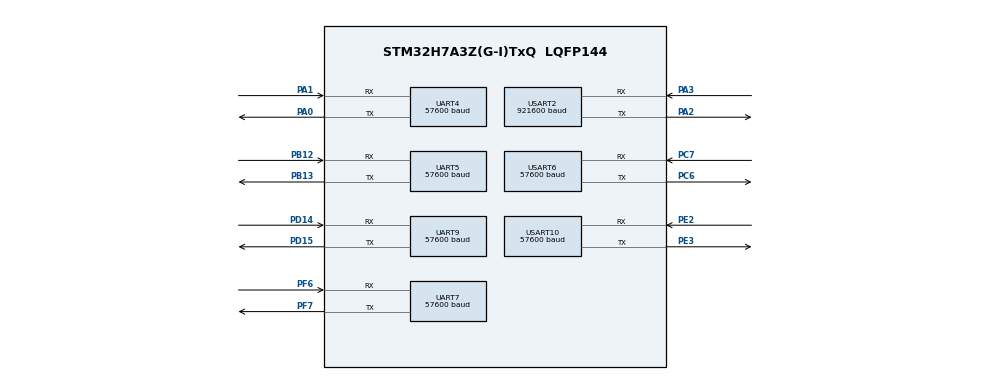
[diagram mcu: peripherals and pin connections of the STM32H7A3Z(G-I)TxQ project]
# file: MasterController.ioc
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CORTEX_M7.CPU_ICache=Enabled
CORTEX_M7.DisableExec_Spec=MPU_INSTRUCTION_ACCESS_DISABLE
CORTEX_M7.default_mode_Activation=1
Dma.Request0=UART4_RX
Dma.Request1=UART5_RX
Dma.Request2=UART7_RX
Dma.Request3=UART9_RX
Dma.Request4=USART2_RX
Dma.Request5=USART6_RX
Dma.Request6=USART10_RX
Dma.UART4_RX.0.Direction=DMA_PERIPH_TO_MEMORY
Dma.UART4_RX.0.EventEnable=DISABLE
Dma.UART4_RX.0.FIFOMode=DMA_FIFOMODE_DISABLE
Dma.UART4_RX.0.Instance=DMA1_Stream0
Dma.UART4_RX.0.MemDataAlignment=DMA_MDATAALIGN_BYTE
Dma.UART4_RX.0.MemInc=DMA_MINC_ENABLE
Dma.UART4_RX.0.Mode=DMA_CIRCULAR
Dma.UART4_RX.0.PeriphDataAlignment=DMA_PDATAALIGN_BYTE
Dma.UART4_RX.0.PeriphInc=DMA_PINC_DISABLE
Dma.UART4_RX.0.Polarity=HAL_DMAMUX_REQ_GEN_RISING
Dma.UART4_RX.0.Priority=DMA_PRIORITY_HIGH
Dma.UART4_RX.0.RequestNumber=1
Dma.UART4_RX.0.SignalID=NONE
Dma.UART4_RX.0.SyncEnable=DISABLE
Dma.UART4_RX.0.SyncPolarity=HAL_DMAMUX_SYNC_NO_EVENT
Dma.UART4_RX.0.SyncRequestNumber=1
Dma.UART4_RX.0.SyncSignalID=NONE
Dma.UART5_RX.1.Direction=DMA_PERIPH_TO_MEMORY
Dma.UART5_RX.1.EventEnable=DISABLE
Dma.UART5_RX.1.FIFOMode=DMA_FIFOMODE_DISABLE
Dma.UART5_RX.1.Instance=DMA1_Stream1
Dma.UART5_RX.1.MemDataAlignment=DMA_MDATAALIGN_BYTE
Dma.UART5_RX.1.MemInc=DMA_MINC_ENABLE
Dma.UART5_RX.1.Mode=DMA_CIRCULAR
Dma.UART5_RX.1.PeriphDataAlignment=DMA_PDATAALIGN_BYTE
Dma.UART5_RX.1.PeriphInc=DMA_PINC_DISABLE
Dma.UART5_RX.1.Polarity=HAL_DMAMUX_REQ_GEN_RISING
Dma.UART5_RX.1.Priority=DMA_PRIORITY_HIGH
Dma.UART5_RX.1.RequestNumber=1
Dma.UART5_RX.1.SignalID=NONE
Dma.UART5_RX.1.SyncEnable=DISABLE
Dma.UART5_RX.1.SyncPolarity=HAL_DMAMUX_SYNC_NO_EVENT
Dma.UART5_RX.1.SyncRequestNumber=1
Dma.UART5_RX.1.SyncSignalID=NONE
Dma.UART7_RX.2.Direction=DMA_PERIPH_TO_MEMORY
Dma.UART7_RX.2.EventEnable=DISABLE
Dma.UART7_RX.2.FIFOMode=DMA_FIFOMODE_DISABLE
Dma.UART7_RX.2.Instance=DMA1_Stream2
Dma.UART7_RX.2.MemDataAlignment=DMA_MDATAALIGN_BYTE
Dma.UART7_RX.2.MemInc=DMA_MINC_ENABLE
Dma.UART7_RX.2.Mode=DMA_CIRCULAR
Dma.UART7_RX.2.PeriphDataAlignment=DMA_PDATAALIGN_BYTE
Dma.UART7_RX.2.PeriphInc=DMA_PINC_DISABLE
Dma.UART7_RX.2.Polarity=HAL_DMAMUX_REQ_GEN_RISING
Dma.UART7_RX.2.Priority=DMA_PRIORITY_HIGH
Dma.UART7_RX.2.RequestNumber=1
Dma.UART7_RX.2.SignalID=NONE
Dma.UART7_RX.2.SyncEnable=DISABLE
Dma.UART7_RX.2.SyncPolarity=HAL_DMAMUX_SYNC_NO_EVENT
Dma.UART7_RX.2.SyncRequestNumber=1
Dma.UART7_RX.2.SyncSignalID=NONE
Dma.UART9_RX.3.Direction=DMA_PERIPH_TO_MEMORY
Dma.UART9_RX.3.EventEnable=DISABLE
Dma.UART9_RX.3.FIFOMode=DMA_FIFOMODE_DISABLE
Dma.UART9_RX.3.Instance=DMA1_Stream3
Dma.UART9_RX.3.MemDataAlignment=DMA_MDATAALIGN_BYTE
Dma.UART9_RX.3.MemInc=DMA_MINC_ENABLE
Dma.UART9_RX.3.Mode=DMA_CIRCULAR
Dma.UART9_RX.3.PeriphDataAlignment=DMA_PDATAALIGN_BYTE
Dma.UART9_RX.3.PeriphInc=DMA_PINC_DISABLE
Dma.UART9_RX.3.Polarity=HAL_DMAMUX_REQ_GEN_RISING
Dma.UART9_RX.3.Priority=DMA_PRIORITY_HIGH
Dma.UART9_RX.3.RequestNumber=1
Dma.UART9_RX.3.SignalID=NONE
Dma.UART9_RX.3.SyncEnable=DISABLE
Dma.UART9_RX.3.SyncPolarity=HAL_DMAMUX_SYNC_NO_EVENT
Dma.UART9_RX.3.SyncRequestNumber=1
Dma.UART9_RX.3.SyncSignalID=NONE
Dma.USART10_RX.6.Direction=DMA_PERIPH_TO_MEMORY
Dma.USART10_RX.6.EventEnable=DISABLE
Dma.USART10_RX.6.FIFOMode=DMA_FIFOMODE_DISABLE
Dma.USART10_RX.6.Instance=DMA1_Stream6
Dma.USART10_RX.6.MemDataAlignment=DMA_MDATAALIGN_BYTE
Dma.USART10_RX.6.MemInc=DMA_MINC_ENABLE
Dma.USART10_RX.6.Mode=DMA_CIRCULAR
Dma.USART10_RX.6.PeriphDataAlignment=DMA_PDATAALIGN_BYTE
Dma.USART10_RX.6.PeriphInc=DMA_PINC_DISABLE
Dma.USART10_RX.6.Polarity=HAL_DMAMUX_REQ_GEN_RISING
Dma.USART10_RX.6.Priority=DMA_PRIORITY_HIGH
Dma.USART10_RX.6.RequestNumber=1
Dma.USART10_RX.6.SignalID=NONE
Dma.USART10_RX.6.SyncEnable=DISABLE
Dma.USART10_RX.6.SyncPolarity=HAL_DMAMUX_SYNC_NO_EVENT
Dma.USART10_RX.6.SyncRequestNumber=1
Dma.USART10_RX.6.SyncSignalID=NONE
Dma.USART2_RX.4.Direction=DMA_PERIPH_TO_MEMORY
Dma.USART2_RX.4.EventEnable=DISABLE
Dma.USART2_RX.4.FIFOMode=DMA_FIFOMODE_DISABLE
Dma.USART2_RX.4.Instance=DMA1_Stream4
Dma.USART2_RX.4.MemDataAlignment=DMA_MDATAALIGN_BYTE
Dma.USART2_RX.4.MemInc=DMA_MINC_ENABLE
Dma.USART2_RX.4.Mode=DMA_CIRCULAR
Dma.USART2_RX.4.PeriphDataAlignment=DMA_PDATAALIGN_BYTE
Dma.USART2_RX.4.PeriphInc=DMA_PINC_DISABLE
Dma.USART2_RX.4.Polarity=HAL_DMAMUX_REQ_GEN_RISING
Dma.USART2_RX.4.Priority=DMA_PRIORITY_HIGH
Dma.USART2_RX.4.RequestNumber=1
Dma.USART2_RX.4.SignalID=NONE
Dma.USART2_RX.4.SyncEnable=DISABLE
Dma.USART2_RX.4.SyncPolarity=HAL_DMAMUX_SYNC_NO_EVENT
Dma.USART2_RX.4.SyncRequestNumber=1
Dma.USART2_RX.4.SyncSignalID=NONE
Dma.USART6_RX.5.Direction=DMA_PERIPH_TO_MEMORY
Dma.USART6_RX.5.EventEnable=DISABLE
Dma.USART6_RX.5.FIFOMode=DMA_FIFOMODE_DISABLE
Dma.USART6_RX.5.Instance=DMA1_Stream5
Dma.USART6_RX.5.MemDataAlignment=DMA_MDATAALIGN_BYTE
Dma.USART6_RX.5.MemInc=DMA_MINC_ENABLE
Dma.USART6_RX.5.Mode=DMA_CIRCULAR
Dma.USART6_RX.5.PeriphDataAlignment=DMA_PDATAALIGN_BYTE
Dma.USART6_RX.5.PeriphInc=DMA_PINC_DISABLE
Dma.USART6_RX.5.Polarity=HAL_DMAMUX_REQ_GEN_RISING
Dma.USART6_RX.5.Priority=DMA_PRIORITY_HIGH
Dma.USART6_RX.5.RequestNumber=1
Dma.USART6_RX.5.SignalID=NONE
Dma.USART6_RX.5.SyncEnable=DISABLE
Dma.USART6_RX.5.SyncPolarity=HAL_DMAMUX_SYNC_NO_EVENT
Dma.USART6_RX.5.SyncRequestNumber=1
Dma.USART6_RX.5.SyncSignalID=NONE
IWDG1.Prescaler=IWDG_PRESCALER_32
IWDG1.Reload=1000
Mcu.Family=STM32H7
Mcu.Name=STM32H7A3Z(G-I)TxQ
Mcu.Package=LQFP144
NUCLEO-H7A3ZI-Q.BUTTON=1
NUCLEO-H7A3ZI-Q.LD1=true
NUCLEO-H7A3ZI-Q.LD2=true
NUCLEO-H7A3ZI-Q.LD3=true
NUCLEO-H7A3ZI-Q.VCP=true
NVIC.DMA1_Stream0_IRQn=true\:0\:0\:false\:false\:true\:false\:true\:true
NVIC.DMA1_Stream1_IRQn=true\:0\:0\:false\:false\:true\:false\:true\:true
NVIC.DMA1_Stream2_IRQn=true\:0\:0\:false\:false\:true\:false\:true\:true
NVIC.DMA1_Stream3_IRQn=true\:0\:0\:false\:false\:true\:false\:true\:true
NVIC.DMA1_Stream4_IRQn=true\:0\:0\:false\:false\:true\:false\:true\:true
NVIC.DMA1_Stream5_IRQn=true\:0\:0\:false\:false\:true\:false\:true\:true
NVIC.DMA1_Stream6_IRQn=true\:0\:0\:false\:false\:true\:false\:true\:true
NVIC.EXTI15_10_IRQn=true\:0\:0\:false\:false\:true\:false\:true\:true
NVIC.PriorityGroup=NVIC_PRIORITYGROUP_4
NVIC.UART4_IRQn=true\:0\:0\:false\:false\:true\:true\:true\:true
NVIC.UART5_IRQn=true\:0\:0\:false\:false\:true\:true\:true\:true
NVIC.UART7_IRQn=true\:0\:0\:false\:false\:true\:true\:true\:true
NVIC.UART9_IRQn=true\:0\:0\:false\:false\:true\:true\:true\:true
NVIC.USART10_IRQn=true\:0\:0\:false\:false\:true\:true\:true\:true
NVIC.USART2_IRQn=true\:0\:0\:false\:false\:true\:true\:true\:true
NVIC.USART6_IRQn=true\:0\:0\:false\:false\:true\:true\:true\:true
PA0.Mode=Asynchronous
PA0.Signal=UART4_TX
PA1.GPIO_PuPd=GPIO_PULLUP
PA1.Mode=Asynchronous
PA1.Signal=UART4_RX
PA13.Mode=Serial_Wire
PA13.Signal=DEBUG_JTMS-SWDIO
PA14.Mode=Serial_Wire
PA14.Signal=DEBUG_JTCK-SWCLK
PA2.Mode=Asynchronous
PA2.Signal=USART2_TX
PA3.GPIO_PuPd=GPIO_PULLUP
PA3.Mode=Asynchronous
PA3.Signal=USART2_RX
PB12.GPIO_PuPd=GPIO_PULLUP
PB12.Mode=Asynchronous
PB12.Signal=UART5_RX
PB13.Mode=Asynchronous
PB13.Signal=UART5_TX
PC14-OSC32_IN.GPIO_Label=OSC32_IN
PC14-OSC32_IN.Signal=RCC_OSC32_IN
PC15-OSC32_OUT.GPIO_Label=OSC32_OUT
PC15-OSC32_OUT.Signal=RCC_OSC32_OUT
PC6.Mode=Asynchronous
PC6.Signal=USART6_TX
PC7.GPIO_PuPd=GPIO_PULLUP
PC7.Mode=Asynchronous
PC7.Signal=USART6_RX
PD14.GPIO_PuPd=GPIO_PULLUP
PD14.Mode=Asynchronous
PD14.Signal=UART9_RX
PD15.Mode=Asynchronous
PD15.Signal=UART9_TX
PD8.Signal=USART3_TX
PD9.Signal=USART3_RX
PE2.GPIO_PuPd=GPIO_PULLUP
PE2.Mode=Asynchronous
PE2.Signal=USART10_RX
PE3.Mode=Asynchronous
PE3.Signal=USART10_TX
PF6.GPIO_PuPd=GPIO_PULLUP
PF6.Mode=Asynchronous
PF6.Signal=UART7_RX
PF7.Mode=Asynchronous
PF7.Signal=UART7_TX
PH0-OSC_IN.GPIO_Label=PH0-MCU
PH0-OSC_IN.Mode=HSE-External-Oscillator
PH0-OSC_IN.Signal=RCC_OSC_IN
PH1-OSC_OUT.GPIO_Label=PH1-MCU
PH1-OSC_OUT.Mode=HSE-External-Oscillator
PH1-OSC_OUT.Signal=RCC_OSC_OUT
ProjectManager.HeapSize=0x200
ProjectManager.StackSize=0x2000
ProjectManager.TargetToolchain=STM32CubeIDE
RCC.ADCFreq_Value=129000000
RCC.APB1Freq_Value=140000000
RCC.APB2Freq_Value=140000000
RCC.APB3Freq_Value=140000000
RCC.APB4Freq_Value=140000000
RCC.CDPPRE=RCC_APB3_DIV2
RCC.CDPPRE1=RCC_APB1_DIV2
RCC.CDPPRE2=RCC_APB2_DIV2
RCC.CortexFreq_Value=280000000
RCC.DIVM1=4
RCC.DIVM3=1
RCC.DIVN1=35
RCC.DIVN3=24
RCC.DIVQ1=4
RCC.HCLKFreq_Value=280000000
RCC.HSE_VALUE=8000000
RCC.PLLFRACN=0
RCC.PWR_Regulator_Voltage_Scale=PWR_REGULATOR_VOLTAGE_SCALE0
RCC.SRDPPRE=RCC_APB4_DIV2
RCC.SYSCLKFreq_VALUE=280000000
RCC.SYSCLKSource=RCC_SYSCLKSOURCE_PLLCLK
RCC.SupplySource=PWR_DIRECT_SMPS_SUPPLY
RCC.USBCLockSelection=RCC_USBCLKSOURCE_HSI48
RCC.USBFreq_Value=48000000
UART4.BaudRate=57600
UART4.DMADisableonRxErrorParam=UART_ADVFEATURE_DMA_DISABLEONRXERROR
UART4.OverrunDisableParam=UART_ADVFEATURE_OVERRUN_DISABLE
UART5.BaudRate=57600
UART5.DMADisableonRxErrorParam=UART_ADVFEATURE_DMA_DISABLEONRXERROR
UART5.OverrunDisableParam=UART_ADVFEATURE_OVERRUN_DISABLE
UART7.BaudRate=57600
UART7.DMADisableonRxErrorParam=UART_ADVFEATURE_DMA_DISABLEONRXERROR
UART7.OverrunDisableParam=UART_ADVFEATURE_OVERRUN_DISABLE
UART9.BaudRate=57600
UART9.DMADisableonRxErrorParam=UART_ADVFEATURE_DMA_DISABLEONRXERROR
UART9.OverrunDisableParam=UART_ADVFEATURE_OVERRUN_DISABLE
USART10.BaudRate=57600
USART10.DMADisableonRxErrorParam=ADVFEATURE_DMA_DISABLEONRXERROR
USART10.OverrunDisableParam=ADVFEATURE_OVERRUN_DISABLE
USART10.VirtualMode-Asynchronous=VM_ASYNC
USART2.BaudRate=921600
USART2.DMADisableonRxErrorParam=ADVFEATURE_DMA_DISABLEONRXERROR
USART2.OverrunDisableParam=ADVFEATURE_OVERRUN_DISABLE
USART2.VirtualMode-Asynchronous=VM_ASYNC
USART6.BaudRate=57600
USART6.DMADisableonRxErrorParam=ADVFEATURE_DMA_DISABLEONRXERROR
USART6.OverrunDisableParam=ADVFEATURE_OVERRUN_DISABLE
USART6.VirtualMode-Asynchronous=VM_ASYNC
VP_IWDG1_VS_IWDG.Mode=IWDG_Activate
VP_MEMORYMAP_VS_MEMORYMAP.Mode=CurAppReg
VP_NUCLEO-H7A3ZI-Q_VS_BSP_COMMON.Mode=COMMON
VP_RTC_VS_RTC_Activate.Mode=RTC_Enabled
VP_TIM1_VS_ClockSourceINT.Mode=Internal
board=NUCLEO-H7A3ZI-Q

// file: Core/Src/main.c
/* USER CODE BEGIN Header */
/**
  ******************************************************************************
  * @file           : main.c
  * @brief          : Main program body
  ******************************************************************************
  * @attention
  *
  * Copyright (c) 2026 STMicroelectronics.
  * All rights reserved.
  *
  * This software is licensed under terms that can be found in the LICENSE file
  * in the root directory of this software component.
  * If no LICENSE file comes with this software, it is provided AS-IS.
  *
  ******************************************************************************
  */
/* USER CODE END Header */
#include "main.h"

/* USER CODE BEGIN Includes */
#include "mc_board.h"
/* USER CODE END Includes */

COM_InitTypeDef BspCOMInit;

IWDG_HandleTypeDef hiwdg1;

RTC_HandleTypeDef hrtc;

TIM_HandleTypeDef htim1;

UART_HandleTypeDef huart4;
UART_HandleTypeDef huart5;
UART_HandleTypeDef huart7;
UART_HandleTypeDef huart9;
UART_HandleTypeDef huart2;
UART_HandleTypeDef huart6;
UART_HandleTypeDef huart10;
DMA_HandleTypeDef hdma_uart4_rx;
DMA_HandleTypeDef hdma_uart5_rx;
DMA_HandleTypeDef hdma_uart7_rx;
DMA_HandleTypeDef hdma_uart9_rx;
DMA_HandleTypeDef hdma_usart2_rx;
DMA_HandleTypeDef hdma_usart6_rx;
DMA_HandleTypeDef hdma_usart10_rx;

void SystemClock_Config(void);
static void MPU_Config(void);
static void MX_GPIO_Init(void);
static void MX_DMA_Init(void);
static void MX_IWDG1_Init(void);
static void MX_RTC_Init(void);
static void MX_TIM1_Init(void);
static void MX_UART4_Init(void);
static void MX_UART5_Init(void);
static void MX_UART7_Init(void);
static void MX_UART9_Init(void);
static void MX_USART2_UART_Init(void);
static void MX_USART6_UART_Init(void);
static void MX_USART10_UART_Init(void);

int main(void)
{

  /* MPU Configuration--------------------------------------------------------*/
  MPU_Config();

  /* Enable the CPU Cache */

  /* Enable I-Cache---------------------------------------------------------*/
  SCB_EnableICache();

  /* MCU Configuration--------------------------------------------------------*/

  /* Reset of all peripherals, Initializes the Flash interface and the Systick. */
  HAL_Init();

  /* Configure the system clock */
  SystemClock_Config();

  /* Initialize all configured peripherals */
  MX_GPIO_Init();
  MX_DMA_Init();
  MX_IWDG1_Init();
  MX_RTC_Init();
  MX_TIM1_Init();
  MX_UART4_Init();
  MX_UART5_Init();
  MX_UART7_Init();
  MX_UART9_Init();
  MX_USART2_UART_Init();
  MX_USART6_UART_Init();
  MX_USART10_UART_Init();

  /* Initialize leds */
  BSP_LED_Init(LED_GREEN);
  BSP_LED_Init(LED_YELLOW);
  BSP_LED_Init(LED_RED);

  /* Initialize USER push-button, will be used to trigger an interrupt each time it's pressed.*/
  BSP_PB_Init(BUTTON_USER, BUTTON_MODE_EXTI);

  /* Initialize COM1 port (115200, 8 bits (7-bit data + 1 stop bit), no parity */
  BspCOMInit.BaudRate   = 115200;
  BspCOMInit.WordLength = COM_WORDLENGTH_8B;
  BspCOMInit.StopBits   = COM_STOPBITS_1;
  BspCOMInit.Parity     = COM_PARITY_NONE;
  BspCOMInit.HwFlowCtl  = COM_HWCONTROL_NONE;
  if (BSP_COM_Init(COM1, &BspCOMInit) != BSP_ERROR_NONE)
  {
    Error_Handler();
  }

  /* Infinite loop */
  /* USER CODE BEGIN WHILE */
  /* Everything after this point is the MasterController (Core/Src/mc_*.c). */
  mc_board_init();
  while (1)
  {

    /* USER CODE END WHILE */

    /* USER CODE BEGIN 3 */
    mc_board_poll();
  }
  /* USER CODE END 3 */
}

void SystemClock_Config(void)
{
  RCC_OscInitTypeDef RCC_OscInitStruct = {0};
  RCC_ClkInitTypeDef RCC_ClkInitStruct = {0};

  /*AXI clock gating */
  RCC->CKGAENR = 0xE003FFFF;

  /** Supply configuration update enable
  */
  HAL_PWREx_ConfigSupply(PWR_DIRECT_SMPS_SUPPLY);

  /** Configure the main internal regulator output voltage
  */
  __HAL_PWR_VOLTAGESCALING_CONFIG(PWR_REGULATOR_VOLTAGE_SCALE0);

  while(!__HAL_PWR_GET_FLAG(PWR_FLAG_VOSRDY)) {}

  /** Initializes the RCC Oscillators according to the specified parameters
  * in the RCC_OscInitTypeDef structure.
  */
  RCC_OscInitStruct.OscillatorType = RCC_OSCILLATORTYPE_HSI|RCC_OSCILLATORTYPE_LSI;
  RCC_OscInitStruct.HSIState = RCC_HSI_DIV1;
  RCC_OscInitStruct.HSICalibrationValue = 64;
  RCC_OscInitStruct.LSIState = RCC_LSI_ON;
  RCC_OscInitStruct.PLL.PLLState = RCC_PLL_ON;
  RCC_OscInitStruct.PLL.PLLSource = RCC_PLLSOURCE_HSI;
  RCC_OscInitStruct.PLL.PLLM = 4;
  RCC_OscInitStruct.PLL.PLLN = 35;
  RCC_OscInitStruct.PLL.PLLP = 2;
  RCC_OscInitStruct.PLL.PLLQ = 4;
  RCC_OscInitStruct.PLL.PLLR = 2;
  RCC_OscInitStruct.PLL.PLLRGE = RCC_PLL1VCIRANGE_3;
  RCC_OscInitStruct.PLL.PLLVCOSEL = RCC_PLL1VCOWIDE;
  RCC_OscInitStruct.PLL.PLLFRACN = 0;
  if (HAL_RCC_OscConfig(&RCC_OscInitStruct) != HAL_OK)
  {
    Error_Handler();
  }

  /** Initializes the CPU, AHB and APB buses clocks
  */
  RCC_ClkInitStruct.ClockType = RCC_CLOCKTYPE_HCLK|RCC_CLOCKTYPE_SYSCLK
                              |RCC_CLOCKTYPE_PCLK1|RCC_CLOCKTYPE_PCLK2
                              |RCC_CLOCKTYPE_D3PCLK1|RCC_CLOCKTYPE_D1PCLK1;
  RCC_ClkInitStruct.SYSCLKSource = RCC_SYSCLKSOURCE_PLLCLK;
  RCC_ClkInitStruct.SYSCLKDivider = RCC_SYSCLK_DIV1;
  RCC_ClkInitStruct.AHBCLKDivider = RCC_HCLK_DIV1;
  RCC_ClkInitStruct.APB3CLKDivider = RCC_APB3_DIV2;
  RCC_ClkInitStruct.APB1CLKDivider = RCC_APB1_DIV2;
  RCC_ClkInitStruct.APB2CLKDivider = RCC_APB2_DIV2;
  RCC_ClkInitStruct.APB4CLKDivider = RCC_APB4_DIV2;

  if (HAL_RCC_ClockConfig(&RCC_ClkInitStruct, FLASH_LATENCY_6) != HAL_OK)
  {
    Error_Handler();
  }
}

static void MX_IWDG1_Init(void)
{

  hiwdg1.Instance = IWDG1;
  hiwdg1.Init.Prescaler = IWDG_PRESCALER_32;
  hiwdg1.Init.Window = 4095;
  hiwdg1.Init.Reload = 1000;
  if (HAL_IWDG_Init(&hiwdg1) != HAL_OK)
  {
    Error_Handler();
  }

}

static void MX_RTC_Init(void)
{

  /** Initialize RTC Only
  */
  hrtc.Instance = RTC;
  hrtc.Init.HourFormat = RTC_HOURFORMAT_24;
  hrtc.Init.AsynchPrediv = 127;
  hrtc.Init.SynchPrediv = 255;
  hrtc.Init.OutPut = RTC_OUTPUT_DISABLE;
  hrtc.Init.OutPutPolarity = RTC_OUTPUT_POLARITY_HIGH;
  hrtc.Init.OutPutType = RTC_OUTPUT_TYPE_OPENDRAIN;
  hrtc.Init.OutPutRemap = RTC_OUTPUT_REMAP_NONE;
  if (HAL_RTC_Init(&hrtc) != HAL_OK)
  {
    Error_Handler();
  }

}

static void MX_TIM1_Init(void)
{

  TIM_ClockConfigTypeDef sClockSourceConfig = {0};
  TIM_MasterConfigTypeDef sMasterConfig = {0};

  htim1.Instance = TIM1;
  htim1.Init.Prescaler = 0;
  htim1.Init.CounterMode = TIM_COUNTERMODE_UP;
  htim1.Init.Period = 65535;
  htim1.Init.ClockDivision = TIM_CLOCKDIVISION_DIV1;
  htim1.Init.RepetitionCounter = 0;
  htim1.Init.AutoReloadPreload = TIM_AUTORELOAD_PRELOAD_DISABLE;
  if (HAL_TIM_Base_Init(&htim1) != HAL_OK)
  {
    Error_Handler();
  }
  sClockSourceConfig.ClockSource = TIM_CLOCKSOURCE_INTERNAL;
  if (HAL_TIM_ConfigClockSource(&htim1, &sClockSourceConfig) != HAL_OK)
  {
    Error_Handler();
  }
  sMasterConfig.MasterOutputTrigger = TIM_TRGO_RESET;
  sMasterConfig.MasterOutputTrigger2 = TIM_TRGO2_RESET;
  sMasterConfig.MasterSlaveMode = TIM_MASTERSLAVEMODE_DISABLE;
  if (HAL_TIMEx_MasterConfigSynchronization(&htim1, &sMasterConfig) != HAL_OK)
  {
    Error_Handler();
  }

}

static void MX_UART4_Init(void)
{

  huart4.Instance = UART4;
  huart4.Init.BaudRate = 57600;
  huart4.Init.WordLength = UART_WORDLENGTH_8B;
  huart4.Init.StopBits = UART_STOPBITS_1;
  huart4.Init.Parity = UART_PARITY_NONE;
  huart4.Init.Mode = UART_MODE_TX_RX;
  huart4.Init.HwFlowCtl = UART_HWCONTROL_NONE;
  huart4.Init.OverSampling = UART_OVERSAMPLING_16;
  huart4.Init.OneBitSampling = UART_ONE_BIT_SAMPLE_DISABLE;
  huart4.Init.ClockPrescaler = UART_PRESCALER_DIV1;
  huart4.AdvancedInit.AdvFeatureInit = UART_ADVFEATURE_RXOVERRUNDISABLE_INIT|UART_ADVFEATURE_DMADISABLEONERROR_INIT;
  huart4.AdvancedInit.OverrunDisable = UART_ADVFEATURE_OVERRUN_DISABLE;
  huart4.AdvancedInit.DMADisableonRxError = UART_ADVFEATURE_DMA_DISABLEONRXERROR;
  if (HAL_UART_Init(&huart4) != HAL_OK)
  {
    Error_Handler();
  }
  if (HAL_UARTEx_SetTxFifoThreshold(&huart4, UART_TXFIFO_THRESHOLD_1_8) != HAL_OK)
  {
    Error_Handler();
  }
  if (HAL_UARTEx_SetRxFifoThreshold(&huart4, UART_RXFIFO_THRESHOLD_1_8) != HAL_OK)
  {
    Error_Handler();
  }
  if (HAL_UARTEx_DisableFifoMode(&huart4) != HAL_OK)
  {
    Error_Handler();
  }

}

static void MX_UART5_Init(void)
{

  huart5.Instance = UART5;
  huart5.Init.BaudRate = 57600;
  huart5.Init.WordLength = UART_WORDLENGTH_8B;
  huart5.Init.StopBits = UART_STOPBITS_1;
  huart5.Init.Parity = UART_PARITY_NONE;
  huart5.Init.Mode = UART_MODE_TX_RX;
  huart5.Init.HwFlowCtl = UART_HWCONTROL_NONE;
  huart5.Init.OverSampling = UART_OVERSAMPLING_16;
  huart5.Init.OneBitSampling = UART_ONE_BIT_SAMPLE_DISABLE;
  huart5.Init.ClockPrescaler = UART_PRESCALER_DIV1;
  huart5.AdvancedInit.AdvFeatureInit = UART_ADVFEATURE_RXOVERRUNDISABLE_INIT|UART_ADVFEATURE_DMADISABLEONERROR_INIT;
  huart5.AdvancedInit.OverrunDisable = UART_ADVFEATURE_OVERRUN_DISABLE;
  huart5.AdvancedInit.DMADisableonRxError = UART_ADVFEATURE_DMA_DISABLEONRXERROR;
  if (HAL_UART_Init(&huart5) != HAL_OK)
  {
    Error_Handler();
  }
  if (HAL_UARTEx_SetTxFifoThreshold(&huart5, UART_TXFIFO_THRESHOLD_1_8) != HAL_OK)
  {
    Error_Handler();
  }
  if (HAL_UARTEx_SetRxFifoThreshold(&huart5, UART_RXFIFO_THRESHOLD_1_8) != HAL_OK)
  {
    Error_Handler();
  }
  if (HAL_UARTEx_DisableFifoMode(&huart5) != HAL_OK)
  {
    Error_Handler();
  }

}

static void MX_UART7_Init(void)
{

  huart7.Instance = UART7;
  huart7.Init.BaudRate = 57600;
  huart7.Init.WordLength = UART_WORDLENGTH_8B;
  huart7.Init.StopBits = UART_STOPBITS_1;
  huart7.Init.Parity = UART_PARITY_NONE;
  huart7.Init.Mode = UART_MODE_TX_RX;
  huart7.Init.HwFlowCtl = UART_HWCONTROL_NONE;
  huart7.Init.OverSampling = UART_OVERSAMPLING_16;
  huart7.Init.OneBitSampling = UART_ONE_BIT_SAMPLE_DISABLE;
  huart7.Init.ClockPrescaler = UART_PRESCALER_DIV1;
  huart7.AdvancedInit.AdvFeatureInit = UART_ADVFEATURE_RXOVERRUNDISABLE_INIT|UART_ADVFEATURE_DMADISABLEONERROR_INIT;
  huart7.AdvancedInit.OverrunDisable = UART_ADVFEATURE_OVERRUN_DISABLE;
  huart7.AdvancedInit.DMADisableonRxError = UART_ADVFEATURE_DMA_DISABLEONRXERROR;
  if (HAL_UART_Init(&huart7) != HAL_OK)
  {
    Error_Handler();
  }
  if (HAL_UARTEx_SetTxFifoThreshold(&huart7, UART_TXFIFO_THRESHOLD_1_8) != HAL_OK)
  {
    Error_Handler();
  }
  if (HAL_UARTEx_SetRxFifoThreshold(&huart7, UART_RXFIFO_THRESHOLD_1_8) != HAL_OK)
  {
    Error_Handler();
  }
  if (HAL_UARTEx_DisableFifoMode(&huart7) != HAL_OK)
  {
    Error_Handler();
  }

}

static void MX_UART9_Init(void)
{

  huart9.Instance = UART9;
  huart9.Init.BaudRate = 57600;
  huart9.Init.WordLength = UART_WORDLENGTH_8B;
  huart9.Init.StopBits = UART_STOPBITS_1;
  huart9.Init.Parity = UART_PARITY_NONE;
  huart9.Init.Mode = UART_MODE_TX_RX;
  huart9.Init.HwFlowCtl = UART_HWCONTROL_NONE;
  huart9.Init.OverSampling = UART_OVERSAMPLING_16;
  huart9.Init.OneBitSampling = UART_ONE_BIT_SAMPLE_DISABLE;
  huart9.Init.ClockPrescaler = UART_PRESCALER_DIV1;
  huart9.AdvancedInit.AdvFeatureInit = UART_ADVFEATURE_RXOVERRUNDISABLE_INIT|UART_ADVFEATURE_DMADISABLEONERROR_INIT;
  huart9.AdvancedInit.OverrunDisable = UART_ADVFEATURE_OVERRUN_DISABLE;
  huart9.AdvancedInit.DMADisableonRxError = UART_ADVFEATURE_DMA_DISABLEONRXERROR;
  if (HAL_UART_Init(&huart9) != HAL_OK)
  {
    Error_Handler();
  }
  if (HAL_UARTEx_SetTxFifoThreshold(&huart9, UART_TXFIFO_THRESHOLD_1_8) != HAL_OK)
  {
    Error_Handler();
  }
  if (HAL_UARTEx_SetRxFifoThreshold(&huart9, UART_RXFIFO_THRESHOLD_1_8) != HAL_OK)
  {
    Error_Handler();
  }
  if (HAL_UARTEx_DisableFifoMode(&huart9) != HAL_OK)
  {
    Error_Handler();
  }

}

static void MX_USART2_UART_Init(void)
{

  huart2.Instance = USART2;
  huart2.Init.BaudRate = 921600;
  huart2.Init.WordLength = UART_WORDLENGTH_8B;
  huart2.Init.StopBits = UART_STOPBITS_1;
  huart2.Init.Parity = UART_PARITY_NONE;
  huart2.Init.Mode = UART_MODE_TX_RX;
  huart2.Init.HwFlowCtl = UART_HWCONTROL_NONE;
  huart2.Init.OverSampling = UART_OVERSAMPLING_16;
  huart2.Init.OneBitSampling = UART_ONE_BIT_SAMPLE_DISABLE;
  huart2.Init.ClockPrescaler = UART_PRESCALER_DIV1;
  huart2.AdvancedInit.AdvFeatureInit = UART_ADVFEATURE_RXOVERRUNDISABLE_INIT|UART_ADVFEATURE_DMADISABLEONERROR_INIT;
  huart2.AdvancedInit.OverrunDisable = UART_ADVFEATURE_OVERRUN_DISABLE;
  huart2.AdvancedInit.DMADisableonRxError = UART_ADVFEATURE_DMA_DISABLEONRXERROR;
  if (HAL_UART_Init(&huart2) != HAL_OK)
  {
    Error_Handler();
  }
  if (HAL_UARTEx_SetTxFifoThreshold(&huart2, UART_TXFIFO_THRESHOLD_1_8) != HAL_OK)
  {
    Error_Handler();
  }
  if (HAL_UARTEx_SetRxFifoThreshold(&huart2, UART_RXFIFO_THRESHOLD_1_8) != HAL_OK)
  {
    Error_Handler();
  }
  if (HAL_UARTEx_DisableFifoMode(&huart2) != HAL_OK)
  {
    Error_Handler();
  }

}

static void MX_USART6_UART_Init(void)
{

  huart6.Instance = USART6;
  huart6.Init.BaudRate = 57600;
  huart6.Init.WordLength = UART_WORDLENGTH_8B;
  huart6.Init.StopBits = UART_STOPBITS_1;
  huart6.Init.Parity = UART_PARITY_NONE;
  huart6.Init.Mode = UART_MODE_TX_RX;
  huart6.Init.HwFlowCtl = UART_HWCONTROL_NONE;
  huart6.Init.OverSampling = UART_OVERSAMPLING_16;
  huart6.Init.OneBitSampling = UART_ONE_BIT_SAMPLE_DISABLE;
  huart6.Init.ClockPrescaler = UART_PRESCALER_DIV1;
  huart6.AdvancedInit.AdvFeatureInit = UART_ADVFEATURE_RXOVERRUNDISABLE_INIT|UART_ADVFEATURE_DMADISABLEONERROR_INIT;
  huart6.AdvancedInit.OverrunDisable = UART_ADVFEATURE_OVERRUN_DISABLE;
  huart6.AdvancedInit.DMADisableonRxError = UART_ADVFEATURE_DMA_DISABLEONRXERROR;
  if (HAL_UART_Init(&huart6) != HAL_OK)
  {
    Error_Handler();
  }
  if (HAL_UARTEx_SetTxFifoThreshold(&huart6, UART_TXFIFO_THRESHOLD_1_8) != HAL_OK)
  {
    Error_Handler();
  }
  if (HAL_UARTEx_SetRxFifoThreshold(&huart6, UART_RXFIFO_THRESHOLD_1_8) != HAL_OK)
  {
    Error_Handler();
  }
  if (HAL_UARTEx_DisableFifoMode(&huart6) != HAL_OK)
  {
    Error_Handler();
  }

}

static void MX_USART10_UART_Init(void)
{

  huart10.Instance = USART10;
  huart10.Init.BaudRate = 57600;
  huart10.Init.WordLength = UART_WORDLENGTH_8B;
  huart10.Init.StopBits = UART_STOPBITS_1;
  huart10.Init.Parity = UART_PARITY_NONE;
  huart10.Init.Mode = UART_MODE_TX_RX;
  huart10.Init.HwFlowCtl = UART_HWCONTROL_NONE;
  huart10.Init.OverSampling = UART_OVERSAMPLING_16;
  huart10.Init.OneBitSampling = UART_ONE_BIT_SAMPLE_DISABLE;
  huart10.Init.ClockPrescaler = UART_PRESCALER_DIV1;
  huart10.AdvancedInit.AdvFeatureInit = UART_ADVFEATURE_RXOVERRUNDISABLE_INIT|UART_ADVFEATURE_DMADISABLEONERROR_INIT;
  huart10.AdvancedInit.OverrunDisable = UART_ADVFEATURE_OVERRUN_DISABLE;
  huart10.AdvancedInit.DMADisableonRxError = UART_ADVFEATURE_DMA_DISABLEONRXERROR;
  if (HAL_UART_Init(&huart10) != HAL_OK)
  {
    Error_Handler();
  }
  if (HAL_UARTEx_SetTxFifoThreshold(&huart10, UART_TXFIFO_THRESHOLD_1_8) != HAL_OK)
  {
    Error_Handler();
  }
  if (HAL_UARTEx_SetRxFifoThreshold(&huart10, UART_RXFIFO_THRESHOLD_1_8) != HAL_OK)
  {
    Error_Handler();
  }
  if (HAL_UARTEx_DisableFifoMode(&huart10) != HAL_OK)
  {
    Error_Handler();
  }

}

static void MX_DMA_Init(void)
{

  /* DMA controller clock enable */
  __HAL_RCC_DMA1_CLK_ENABLE();

  /* DMA interrupt init */
  /* DMA1_Stream0_IRQn interrupt configuration */
  HAL_NVIC_SetPriority(DMA1_Stream0_IRQn, 0, 0);
  HAL_NVIC_EnableIRQ(DMA1_Stream0_IRQn);
  /* DMA1_Stream1_IRQn interrupt configuration */
  HAL_NVIC_SetPriority(DMA1_Stream1_IRQn, 0, 0);
  HAL_NVIC_EnableIRQ(DMA1_Stream1_IRQn);
  /* DMA1_Stream2_IRQn interrupt configuration */
  HAL_NVIC_SetPriority(DMA1_Stream2_IRQn, 0, 0);
  HAL_NVIC_EnableIRQ(DMA1_Stream2_IRQn);
  /* DMA1_Stream3_IRQn interrupt configuration */
  HAL_NVIC_SetPriority(DMA1_Stream3_IRQn, 0, 0);
  HAL_NVIC_EnableIRQ(DMA1_Stream3_IRQn);
  /* DMA1_Stream4_IRQn interrupt configuration */
  HAL_NVIC_SetPriority(DMA1_Stream4_IRQn, 0, 0);
  HAL_NVIC_EnableIRQ(DMA1_Stream4_IRQn);
  /* DMA1_Stream5_IRQn interrupt configuration */
  HAL_NVIC_SetPriority(DMA1_Stream5_IRQn, 0, 0);
  HAL_NVIC_EnableIRQ(DMA1_Stream5_IRQn);
  /* DMA1_Stream6_IRQn interrupt configuration */
  HAL_NVIC_SetPriority(DMA1_Stream6_IRQn, 0, 0);
  HAL_NVIC_EnableIRQ(DMA1_Stream6_IRQn);

}

static void MX_GPIO_Init(void)
{

  /* GPIO Ports Clock Enable */
  __HAL_RCC_GPIOE_CLK_ENABLE();
  __HAL_RCC_GPIOC_CLK_ENABLE();
  __HAL_RCC_GPIOF_CLK_ENABLE();
  __HAL_RCC_GPIOH_CLK_ENABLE();
  __HAL_RCC_GPIOA_CLK_ENABLE();
  __HAL_RCC_GPIOB_CLK_ENABLE();
  __HAL_RCC_GPIOD_CLK_ENABLE();

}

 /* MPU Configuration */

void MPU_Config(void)
{
  MPU_Region_InitTypeDef MPU_InitStruct = {0};

  /* Disables the MPU */
  HAL_MPU_Disable();

  /** Initializes and configures the Region and the memory to be protected
  */
  MPU_InitStruct.Enable = MPU_REGION_ENABLE;
  MPU_InitStruct.Number = MPU_REGION_NUMBER0;
  MPU_InitStruct.BaseAddress = 0x0;
  MPU_InitStruct.Size = MPU_REGION_SIZE_4GB;
  MPU_InitStruct.SubRegionDisable = 0x87;
  MPU_InitStruct.TypeExtField = MPU_TEX_LEVEL0;
  MPU_InitStruct.AccessPermission = MPU_REGION_NO_ACCESS;
  MPU_InitStruct.DisableExec = MPU_INSTRUCTION_ACCESS_DISABLE;
  MPU_InitStruct.IsShareable = MPU_ACCESS_SHAREABLE;
  MPU_InitStruct.IsCacheable = MPU_ACCESS_NOT_CACHEABLE;
  MPU_InitStruct.IsBufferable = MPU_ACCESS_NOT_BUFFERABLE;

  HAL_MPU_ConfigRegion(&MPU_InitStruct);
  /* Enables the MPU */
  HAL_MPU_Enable(MPU_PRIVILEGED_DEFAULT);

}

void Error_Handler(void)
{
  /* USER CODE BEGIN Error_Handler_Debug */
  /* User can add his own implementation to report the HAL error return state */
  mc_board_fatal(MC_FAULT_ERROR_HANDLER);
  /* USER CODE END Error_Handler_Debug */
}
